# STM32F0x0 register map
File version: 1.2
CPU: CM0 r0p0, little endian, no MPU, no FPU, 3 interrupt priority bits
Registers are 32-bit, read-write, reset 0x0 unless marked. A register's access mark holds for its fields unless they carry their own. Offsets are from the block's base; [hi:lo] are bit positions; {n}, {i} and the like mark numbered series.

## USB — Universal serial bus full-speed device interface
Base 0x40005C00
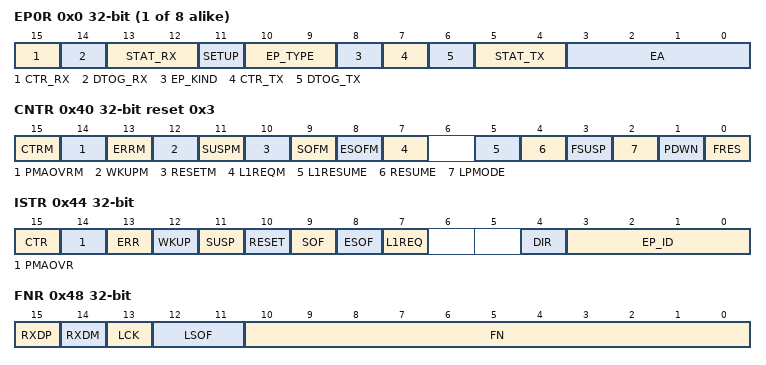
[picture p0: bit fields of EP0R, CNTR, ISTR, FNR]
{0x0+4i} EP{i}R (i=0..7) — endpoint {i} register
  [15] CTR_RX — Correct transfer for reception
  [14] DTOG_RX — Data Toggle, for reception transfers
  [13:12] STAT_RX — Status bits, for reception transfers
  [11] SETUP — Setup transaction completed
  [10:9] EP_TYPE — Endpoint type
  [8] EP_KIND — Endpoint kind
  [7] CTR_TX — Correct Transfer for transmission
  [6] DTOG_TX — Data Toggle, for transmission transfers
  [5:4] STAT_TX — Status bits, for transmission transfers
  [3:0] EA — Endpoint address
0x40 CNTR reset 0x3 — control register
  [15] CTRM — Correct transfer interrupt mask
  [14] PMAOVRM — Packet memory area over / underrun interrupt mask
  [13] ERRM — Error interrupt mask
  [12] WKUPM — Wakeup interrupt mask
  [11] SUSPM — Suspend mode interrupt mask
  [10] RESETM — USB reset interrupt mask
  [9] SOFM — Start of frame interrupt mask
  [8] ESOFM — Expected start of frame interrupt mask
  [7] L1REQM — LPM L1 state request interrupt mask
  [5] L1RESUME — LPM L1 Resume request
  [4] RESUME — Resume request
  [3] FSUSP — Force suspend
  [2] LPMODE — Low-power mode
  [1] PDWN — Power down
  [0] FRES — Force USB Reset
0x44 ISTR access per field — interrupt status register
  [15] CTR ro — Correct transfer
  [14] PMAOVR rw — Packet memory area over / underrun
  [13] ERR rw — Error
  [12] WKUP rw — Wakeup
  [11] SUSP rw — Suspend mode request
  [10] RESET rw — reset request
  [9] SOF rw — start of frame
  [8] ESOF rw — Expected start frame
  [7] L1REQ rw — LPM L1 state request
  [4] DIR ro — Direction of transaction
  [3:0] EP_ID ro — Endpoint Identifier
0x48 FNR ro — frame number register
  [15] RXDP — Receive data + line status
  [14] RXDM — Receive data - line status
  [13] LCK — Locked
  [12:11] LSOF — Lost SOF
  [10:0] FN — Frame number
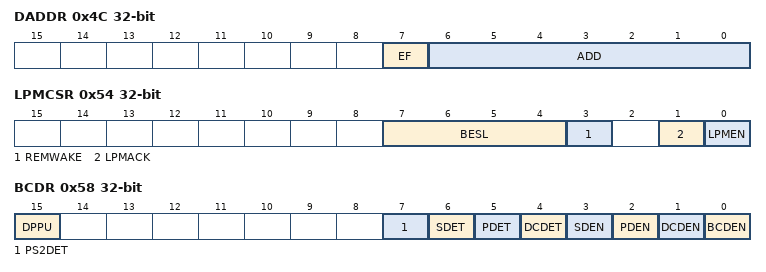
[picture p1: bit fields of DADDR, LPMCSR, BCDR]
0x4C DADDR — device address
  [7] EF — Enable function
  [6:0] ADD — Device address
0x50 BTABLE — Buffer table address
  [15:3] BTABLE — Buffer table
0x54 LPMCSR access per field — LPM control and status register
  [7:4] BESL ro — BESL value
  [3] REMWAKE ro — bRemoteWake value
  [1] LPMACK rw — LPM Token acknowledge enable
  [0] LPMEN rw — LPM support enable
0x58 BCDR access per field — Battery charging detector
  [15] DPPU rw — DP pull-up control
  [7] PS2DET ro — DM pull-up detection status
  [6] SDET ro — Secondary detection (SD) status
  [5] PDET ro — Primary detection (PD) status
  [4] DCDET ro — Data contact detection (DCD) status
  [3] SDEN rw — Secondary detection (SD) mode enable
  [2] PDEN rw — Primary detection (PD) mode enable
  [1] DCDEN rw — Data contact detection (DCD) mode enable
  [0] BCDEN rw — Battery charging detector (BCD) enable

## CRC — cyclic redundancy check calculation unit
Base 0x40023000
0x00 DR reset 0xFFFFFFFF — Data register
  [31:0] DR — Data register bits
0x04 IDR — Independent data register
  [7:0] IDR — General-purpose 8-bit data register bits
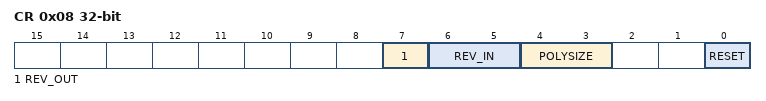
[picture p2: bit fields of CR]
0x08 CR — Control register
  [7] REV_OUT — Reverse output data
  [6:5] REV_IN — Reverse input data
  [4:3] POLYSIZE — Polynomial size
  [0] RESET — reset bit
0x0C INIT reset 0xFFFFFFFF — Initial CRC value
  [31:0] INIT — Programmable initial CRC value

## PWR — Power control
Base 0x40007000
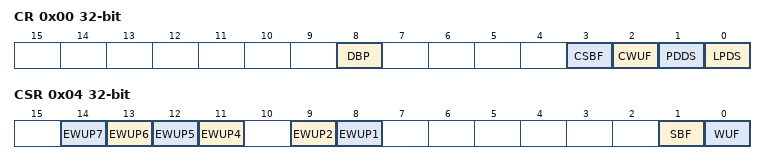
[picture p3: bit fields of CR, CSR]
0x00 CR — power control register
  [8] DBP — Disable backup domain write protection
  [3] CSBF — Clear standby flag
  [2] CWUF — Clear wakeup flag
  [1] PDDS — Power down deepsleep
  [0] LPDS — Low-power deep sleep
0x04 CSR access per field — power control/status register
  [n+7] EWUP{n} rw (n=4..7) — Enable WKUP pin {n}
  [9] EWUP2 rw — Enable WKUP pin 2
  [8] EWUP1 rw — Enable WKUP pin 1
  [1] SBF ro — Standby flag
  [0] WUF ro — Wakeup flag
